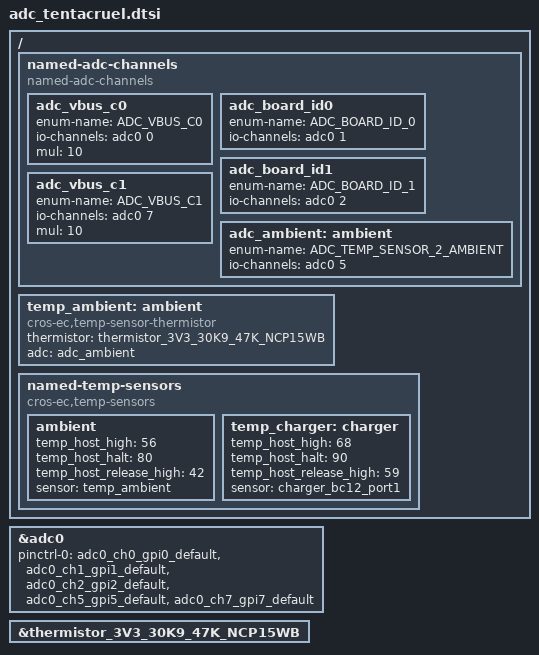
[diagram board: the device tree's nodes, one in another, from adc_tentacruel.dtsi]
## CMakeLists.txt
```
# Copyright 2021 The ChromiumOS Authors
# Use of this source code is governed by a BSD-style license that can be
# found in the LICENSE file.

cmake_minimum_required(VERSION 3.13.1)

find_package(Zephyr REQUIRED HINTS "${ZEPHYR_BASE}")

cros_ec_library_include_directories(include)

# Include selected EC source from the baseboard
zephyr_library_sources(
	"src/board.c"
	"src/hibernate.c"
)

zephyr_library_sources_ifdef(CONFIG_PLATFORM_EC_USBC "src/usbc.c")
zephyr_library_sources_ifdef(CONFIG_PLATFORM_EC_USBC "src/usb_pd_policy.c")
zephyr_library_sources_ifdef(CONFIG_VARIANT_CORSOLA_DB_DETECTION
			     "src/variant_db_detection.c")
zephyr_library_sources_ifndef(CONFIG_CORSOLA_BOARD_CHIPSET_CUSTOM "src/board_chipset.c")

if(DEFINED CONFIG_BOARD_KRABBY)
	project(krabby)
	add_subdirectory(krabby)
elseif(DEFINED CONFIG_BOARD_KINGLER)
	project(kingler)
	add_subdirectory(kingler)
elseif(DEFINED CONFIG_BOARD_KYOGRE)
	project(kyogre)
	add_subdirectory(kyogre)
elseif(DEFINED CONFIG_BOARD_STARMIE)
	project(starmie)
	add_subdirectory(starmie)
elseif(DEFINED CONFIG_BOARD_STEELIX)
	project(steelix)
	add_subdirectory(steelix)
elseif(DEFINED CONFIG_BOARD_TENTACRUEL)
	project(tentacruel)
	add_subdirectory(tentacruel)
elseif(DEFINED CONFIG_BOARD_MAGIKARP)
	project(magikarp)
	add_subdirectory(magikarp)
elseif(DEFINED CONFIG_BOARD_VOLTORB)
	project(voltorb)
	add_subdirectory(voltorb)
elseif(DEFINED CONFIG_BOARD_PONYTA)
	project(ponyta)
	add_subdirectory(ponyta)
elseif(DEFINED CONFIG_BOARD_CHINCHOU)
	project(chinchou)
	add_subdirectory(chinchou)
elseif(DEFINED CONFIG_BOARD_WOOBAT)
	project(woobat)
	add_subdirectory(woobat)
elseif(DEFINED CONFIG_BOARD_WUGTRIO)
	project(wugtrio)
	add_subdirectory(wugtrio)
elseif(DEFINED CONFIG_BOARD_SKITTY)
	project(skitty)
	add_subdirectory(skitty)
elseif(DEFINED CONFIG_BOARD_VELUZA)
	project(veluza)
	add_subdirectory(veluza)
elseif(DEFINED CONFIG_BOARD_SQUIRTLE)
	project(squirtle)
	add_subdirectory(squirtle)
elseif(DEFINED CONFIG_BOARD_WYRDEER)
	project(wyrdeer)
	add_subdirectory(wyrdeer)
endif()
```

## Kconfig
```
# Copyright 2021 The ChromiumOS Authors
# Use of this source code is governed by a BSD-style license that can be
# found in the LICENSE file.

config BOARD_KRABBY
	bool "Google Krabby Board"
	help
	  Build Google Krabby reference board. Krabby has MediaTek MT8186 SoC
	  with ITE it81202-bx EC.

config BOARD_KINGLER
	bool "Google Kingler Board"
	help
	  Build Google Kingler reference board. Krabby has MediaTek MT8186 SoC
	  with NPCX993FA0BX EC.

config BOARD_KYOGRE
	bool "Google Kyogre Board"
	help
	  Build Google Kyogre variant board. Kyogre is a variant of Kingler
	  and has MediaTek MT8186 SoC with NPCX993FA0BX EC.

config BOARD_STARMIE
	bool "Google Starmie Board"
	help
	  Build Google Starmie variant board. Starmie is a variant of Krabby
	  and has MediaTek MT8186 SoC with ITE it81202-bx EC

config BOARD_STEELIX
	bool "Google Steelix Board"
	help
	  Build Google Steelix variant board. Steelix is a variant of Kingler
	  and has MediaTek MT8186 SoC with NPCX993FA0BX EC.

config BOARD_TENTACRUEL
	bool "Google Tentacruel Board"
	help
	  Build Google Tentacruel variant board. Tentacruel is a variant of Krabby
	  and has MediaTek MT8186 SoC with ITE it81202-bx EC.

config BOARD_MAGIKARP
	bool "Google Magikarp Board"
	help
	  Build Google Magikarp variant board. Magikarp is a variant of Krabby
	  and has MediaTek MT8186 SoC with ITE it81202-bx EC.

config BOARD_VOLTORB
	bool "Google Voltorb Board"
	help
	  Build Google Voltorb variant board. Voltorb is a variant of Kingler
	  and has MediaTek MT8186/MT8186T SoC with NPCX993FA0BX EC.

config BOARD_PONYTA
	bool "Google Ponyta Board"
	help
	  Build Google Ponyta variant board. Ponyta is a variant of Kingler
	  and has MediaTek MT8186 SoC with NPCX993FA0BX EC.

config BOARD_CHINCHOU
	bool "Google Chinchou Board"
	help
	  Build Google Chinchou variant board. Chinchou is a variant of Krabby
	  and has MediaTek MT8186 SoC with ITE it81202-bx EC

config BOARD_WOOBAT
	bool "Google Woobat Board"
	help
	  Build Google Woobat variant board. Woobat is a variant of Krabby
	  and has MediaTek MT8186 SoC with ITE it81202-bx EC

config BOARD_WUGTRIO
	bool "Google Wugtrio Board"
	help
	  Build Google Wugtrio variant board. Wugtrio is a variant of Krabby
	  and has MediaTek MT8186 SoC with ITE it81202-bx EC

config BOARD_SKITTY
	bool "Google Skitty Board"
	help
	  Build Google Skitty variant board. Skitty is a variant of Krabby
	  and has MediaTek MT8186 SoC with ITE it81202-bx EC

config BOARD_VELUZA
	bool "Google Veluza Board"
	help
	  Build Google Veluza variant board. Veluza is a variant of Krabby
	  and has MediaTek MT8186 SoC with ITE it81202-bx EC

config BOARD_SQUIRTLE
	bool "Google Squirtle Board"
	help
	  Build Google Squirtle variant board. Squirtle is a variant of Kingler
	  and has MediaTek MT8186/MT8186T SoC with NPCX993FA0BX EC.

config BOARD_WYRDEER
	bool "Google Wyrdeer Board"
	help
	  Build Google Wyrdeer variant board. Wyrdeer is a variant of Krabby
	  and has MediaTek MT8186 SoC with ITE it81202-bx EC

config VARIANT_CORSOLA_DB_DETECTION
	bool "Corsola Platform Runtime Daughter Board Detection"
	depends on PLATFORM_EC_USB_PD_TCPC_RUNTIME_CONFIG
	depends on PLATFORM_EC_USB_MUX_RUNTIME_CONFIG
	help
	  Daughter board detection for Type-C subboard or HDMI subboard. This
          includes pin configuration and driver loading.
	default y

config CORSOLA_HIBERNATE_PRE_OFF_5V
	bool "Corsola Platform Hibernate Power Sequence Selection"
	help
	  Set PP5000_Z2 to deactivate before executing normal corsola hibernate.
	default n

config CORSOLA_BOARD_CHIPSET_CUSTOM
	bool "Corsola Platform Board Chipset Customization"
	help
	  Enable corsola platform customized AP power callbacks.
	default n

source "Kconfig.zephyr"
```

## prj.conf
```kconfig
# Copyright 2021 The ChromiumOS Authors
# Use of this source code is governed by a BSD-style license that can be
# found in the LICENSE file.
#

# http://google3/hardware/standards/usb/
CONFIG_PLATFORM_EC_USB_PID=0x505C

# CROS EC
CONFIG_CROS_EC=y
CONFIG_PLATFORM_EC=y
CONFIG_PLATFORM_EC_SWITCH=y
CONFIG_SHIMMED_TASKS=y

# AP SoC configuration
CONFIG_AP=y
CONFIG_AP_ARM_MTK_MT8186=y

# Variant config
CONFIG_VARIANT_CORSOLA_DB_DETECTION=y

# Shell features
CONFIG_KERNEL_SHELL=y
CONFIG_SHELL_HELP=y
CONFIG_SHELL_HISTORY=y
CONFIG_SHELL_TAB=y
CONFIG_SHELL_TAB_AUTOCOMPLETION=y

# CBI
CONFIG_EEPROM=y
CONFIG_EEPROM_SHELL=n
CONFIG_PLATFORM_EC_BOARD_VERSION_CBI=y

# Keyboard
CONFIG_PLATFORM_EC_KEYBOARD=y
CONFIG_PLATFORM_EC_KEYBOARD_PROTOCOL_MKBP=y
CONFIG_PLATFORM_EC_KEYBOARD_COL2_INVERTED=y

# MKBP
CONFIG_PLATFORM_EC_MKBP_EVENT=y
CONFIG_PLATFORM_EC_MKBP_INPUT_DEVICES=y
CONFIG_PLATFORM_EC_MKBP_USE_GPIO=y

# EFS2
CONFIG_PLATFORM_EC_VBOOT_EFS2=y

# USB
CONFIG_PLATFORM_EC_USB_PD_TBT_COMPAT_MODE=n
CONFIG_PLATFORM_EC_USB_PD_USB32_DRD=n
CONFIG_PLATFORM_EC_USB_PD_USB4=n
CONFIG_PLATFORM_EC_USB_PORT_POWER_DUMB_CUSTOM_HOOK=y

# USB-C
CONFIG_PLATFORM_EC_USBC=y
CONFIG_PLATFORM_EC_USBC_SS_MUX_DFP_ONLY=y
CONFIG_PLATFORM_EC_USB_PD_DPS=y
CONFIG_PLATFORM_EC_USB_PD_DP_HPD_GPIO=y
CONFIG_PLATFORM_EC_USB_PD_DP_HPD_GPIO_CUSTOM=y
CONFIG_PLATFORM_EC_USB_PD_FRS=y
CONFIG_PLATFORM_EC_USB_PD_CLEAR_HARD_RESET_STATUS=y

# Power Seq
CONFIG_PLATFORM_EC_CHIPSET_RESUME_INIT_HOOK=y
CONFIG_PLATFORM_EC_EXTPOWER_GPIO=y
CONFIG_PLATFORM_EC_POWERSEQ=y
CONFIG_PLATFORM_EC_POWERSEQ_HOST_SLEEP=y
CONFIG_PLATFORM_EC_POWERSEQ_PP5000_CONTROL=n
CONFIG_PLATFORM_EC_POWER_SLEEP_FAILURE_DETECTION=y

# Optional features
CONFIG_FLASH_SHELL=n

# EEPROM
CONFIG_PLATFORM_EC_EEPROM_CBI_WP=y

# Host Commands
CONFIG_PLATFORM_EC_HOSTCMD=y

# Battery
CONFIG_PLATFORM_EC_BATTERY_CUT_OFF=y
CONFIG_PLATFORM_EC_BATTERY_FUEL_GAUGE=y
CONFIG_PLATFORM_EC_BATTERY_PRESENT_GPIO=y
CONFIG_PLATFORM_EC_BATTERY_SMART=y
CONFIG_PLATFORM_EC_BATT_FULL_CHIPSET_OFF_INPUT_LIMIT_MV=9000
CONFIG_PLATFORM_EC_I2C_PASSTHRU_RESTRICTED=y
CONFIG_PLATFORM_EC_I2C_VIRTUAL_BATTERY=y

# Charger
CONFIG_PLATFORM_EC_BC12_CLIENT_MODE_ONLY_PI3USB9201=y
CONFIG_PLATFORM_EC_CHARGE_MANAGER=y

# Button
CONFIG_PLATFORM_EC_CMD_BUTTON=y
CONFIG_PLATFORM_EC_POWER_BUTTON=y
CONFIG_PLATFORM_EC_VOLUME_BUTTONS=y
```

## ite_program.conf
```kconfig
# Copyright 2022 The ChromiumOS Authors
# Use of this source code is governed by a BSD-style license that can be
# found in the LICENSE file.

# Bring up options
CONFIG_SHELL_HISTORY_BUFFER=256
CONFIG_PLATFORM_EC_SYSTEM_UNLOCKED=y
CONFIG_PLATFORM_EC_BRINGUP=y

# Power Sequencing
CONFIG_PLATFORM_EC_CHIPSET_RESET_HOOK=y

# Lid Switch
CONFIG_PLATFORM_EC_LID_SWITCH=y

# Charger
CONFIG_PLATFORM_EC_CHARGE_RAMP_HW=y
CONFIG_PLATFORM_EC_CHARGER_DISCHARGE_ON_AC=y
CONFIG_PLATFORM_EC_CHARGER_DISCHARGE_ON_AC_CHARGER=y
CONFIG_PLATFORM_EC_CHARGER_MAINTAIN_VBAT=y
CONFIG_PLATFORM_EC_CHARGER_PSYS=y
CONFIG_PLATFORM_EC_CHARGER_PSYS_READ=y
# BOARD_RS2
CONFIG_PLATFORM_EC_CHARGER_SENSE_RESISTOR=10
# BOARD_RS1
CONFIG_PLATFORM_EC_CHARGER_SENSE_RESISTOR_AC=20
CONFIG_PLATFORM_EC_CONSOLE_CMD_CHARGER_DUMP=y

# Host Commands
CONFIG_PLATFORM_EC_CONSOLE_CMD_ACCELS=y
CONFIG_PLATFORM_EC_CONSOLE_CMD_ACCEL_INFO=y
CONFIG_PLATFORM_EC_CONSOLE_CMD_CHARGER_ADC_AMON_BMON=y
CONFIG_PLATFORM_EC_CONSOLE_CMD_SYSINFO=y
CONFIG_PLATFORM_EC_HOST_COMMAND_STATUS=y

# Sensors
CONFIG_PLATFORM_EC_ACCEL_FIFO=y
CONFIG_PLATFORM_EC_GMR_TABLET_MODE=y
CONFIG_PLATFORM_EC_LID_ANGLE=y
CONFIG_PLATFORM_EC_LID_ANGLE_UPDATE=y
CONFIG_PLATFORM_EC_SENSOR_TIGHT_TIMESTAMPS=y
CONFIG_PLATFORM_EC_TABLET_MODE=y
CONFIG_PLATFORM_EC_TABLET_MODE_SWITCH=y
CONFIG_PLATFORM_EC_MAX_SENSOR_FREQ_MILLIHZ=100000

# Sensor Drivers
CONFIG_PLATFORM_EC_ACCEL_LIS2DW12=y
CONFIG_PLATFORM_EC_ACCELGYRO_ICM42607=y
CONFIG_PLATFORM_EC_ACCELGYRO_ICM_COMM_I2C=y

# Tasks
CONFIG_TASK_CHARGER_STACK_SIZE=1440
CONFIG_TASK_CHIPSET_STACK_SIZE=1440
CONFIG_TASK_MOTIONSENSE_STACK_SIZE=1280
CONFIG_TASK_PD_STACK_SIZE=1280

# USB-C
CONFIG_PLATFORM_EC_USBC_PPC_SYV682C=y
CONFIG_PLATFORM_EC_USB_PD_DISCHARGE_PPC=y
CONFIG_PLATFORM_EC_USB_PD_FRS_PPC=y
CONFIG_PLATFORM_EC_USB_PD_LOGGING=y
CONFIG_PLATFORM_EC_USB_PD_VBUS_DETECT_PPC=y
CONFIG_PLATFORM_EC_USB_PD_VBUS_MEASURE_ADC_EACH_PORT=y
CONFIG_PLATFORM_EC_USB_PD_DUAL_ROLE_AUTO_TOGGLE=n
CONFIG_PLATFORM_EC_USB_PD_3A_PORTS=0
CONFIG_PLATFORM_EC_USB_PD_PULLUP=1

# TODO(b/180980668): bring these features up
CONFIG_PLATFORM_EC_BACKLIGHT_LID=n

# Decrease TX shell backend buffer to save RAM
CONFIG_SHELL_BACKEND_SERIAL_TX_RING_BUFFER_SIZE=128
```

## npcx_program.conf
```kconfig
# Copyright 2022 The ChromiumOS Authors
# Use of this source code is governed by a BSD-style license that can be
# found in the LICENSE file.


# Bring up options
CONFIG_PLATFORM_EC_SYSTEM_UNLOCKED=y

# Debug options and features; can be disabled to save memory or once bringup
# is complete.
CONFIG_SHELL_MINIMAL=n

# Charger
CONFIG_PLATFORM_EC_CHARGER_DISCHARGE_ON_AC=y
CONFIG_PLATFORM_EC_CHARGER_ISL9238C=y
CONFIG_PLATFORM_EC_CHARGER_PSYS=y
CONFIG_PLATFORM_EC_CHARGER_PSYS_READ=y
CONFIG_PLATFORM_EC_CHARGER_SENSE_RESISTOR=10
CONFIG_PLATFORM_EC_CHARGER_SENSE_RESISTOR_AC=20
CONFIG_PLATFORM_EC_CONSOLE_CMD_CHARGER_ADC_AMON_BMON=y

# PWM
CONFIG_PWM=y

# LED
CONFIG_PLATFORM_EC_LED_COMMON=y
CONFIG_PLATFORM_EC_LED_ONOFF_STATES=y

# Math
CONFIG_PLATFORM_EC_MATH_UTIL=y

# Power sequencing
CONFIG_PLATFORM_EC_POWERSEQ_MT8186=y
CONFIG_PLATFORM_EC_POWERSEQ_S4=n

# Button
CONFIG_PLATFORM_EC_BUTTONS_RUNTIME_CONFIG=y

# Sensors
CONFIG_PLATFORM_EC_ACCELGYRO_BMI3XX=y
CONFIG_PLATFORM_EC_ACCELGYRO_BMI_COMM_I2C=y
CONFIG_PLATFORM_EC_ACCEL_FIFO=y
CONFIG_PLATFORM_EC_CONSOLE_CMD_ACCELS=y
CONFIG_PLATFORM_EC_CONSOLE_CMD_ACCEL_INFO=y
CONFIG_PLATFORM_EC_GMR_TABLET_MODE=y
CONFIG_PLATFORM_EC_LID_ANGLE=y
CONFIG_PLATFORM_EC_LID_ANGLE_UPDATE=y
CONFIG_PLATFORM_EC_LID_SWITCH=y
CONFIG_PLATFORM_EC_SENSOR_TIGHT_TIMESTAMPS=y
CONFIG_PLATFORM_EC_TABLET_MODE=y
CONFIG_PLATFORM_EC_TABLET_MODE_SWITCH=y

# USBC
CONFIG_PLATFORM_EC_PD_POWER_SUPPLY_TURN_OFF_DELAY=15000
CONFIG_PLATFORM_EC_PD_POWER_SUPPLY_TURN_ON_DELAY=15000
CONFIG_PLATFORM_EC_USBC_PPC=y
CONFIG_PLATFORM_EC_USBC_PPC_RT1718S=n
CONFIG_PLATFORM_EC_USB_PD_DISCHARGE_PPC=y
CONFIG_PLATFORM_EC_USB_PD_FRS_TCPC=y
CONFIG_PLATFORM_EC_USB_PD_LOGGING=y
CONFIG_PLATFORM_EC_USB_PD_DEBUG_FIXED_LEVEL=y
CONFIG_PLATFORM_EC_USB_PD_DEBUG_LEVEL=2
CONFIG_PLATFORM_EC_USB_PD_TCPM_ANX7447_AUX_PU_PD=y
CONFIG_PLATFORM_EC_USB_PD_TCPM_SBU=y
CONFIG_PLATFORM_EC_USB_PD_VBUS_DETECT_TCPC=y
CONFIG_PLATFORM_EC_USB_PD_VBUS_MEASURE_BY_BOARD=y

# External power
CONFIG_PLATFORM_EC_BACKLIGHT_LID=n

# Keyboard
CONFIG_CROS_KB_RAW_NPCX_KSO_HIGH_DRIVE=y

CONFIG_SYSCON=y

CONFIG_PLATFORM_EC_BOARD_VERSION_GPIO=n
```

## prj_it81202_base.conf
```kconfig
# Copyright 2022 The ChromiumOS Authors
# Use of this source code is governed by a BSD-style license that can be
# found in the LICENSE file.

# Bring up options
CONFIG_SHELL_HISTORY_BUFFER=256
CONFIG_PLATFORM_EC_SYSTEM_UNLOCKED=y
CONFIG_PLATFORM_EC_BRINGUP=y

# Power Sequencing
CONFIG_PLATFORM_EC_CHIPSET_RESET_HOOK=y

# Lid Switch
CONFIG_PLATFORM_EC_LID_SWITCH=y

# Charger
CONFIG_PLATFORM_EC_CHARGE_RAMP_HW=y
CONFIG_PLATFORM_EC_CHARGER_DISCHARGE_ON_AC=y
CONFIG_PLATFORM_EC_CHARGER_DISCHARGE_ON_AC_CHARGER=y
CONFIG_PLATFORM_EC_CHARGER_MAINTAIN_VBAT=y
CONFIG_PLATFORM_EC_CHARGER_PSYS=y
CONFIG_PLATFORM_EC_CHARGER_PSYS_READ=y
# BOARD_RS2
CONFIG_PLATFORM_EC_CHARGER_SENSE_RESISTOR=10
# BOARD_RS1
CONFIG_PLATFORM_EC_CHARGER_SENSE_RESISTOR_AC=20
CONFIG_PLATFORM_EC_CONSOLE_CMD_CHARGER_DUMP=y

# Host Commands
CONFIG_PLATFORM_EC_CONSOLE_CMD_ACCELS=y
CONFIG_PLATFORM_EC_CONSOLE_CMD_ACCEL_INFO=y
CONFIG_PLATFORM_EC_CONSOLE_CMD_CHARGER_ADC_AMON_BMON=y
CONFIG_PLATFORM_EC_CONSOLE_CMD_SYSINFO=y
CONFIG_PLATFORM_EC_HOST_COMMAND_STATUS=y

# LED
CONFIG_PLATFORM_EC_LED_DT=y

# PWM
CONFIG_PWM=y
CONFIG_PWM_SHELL=n

# Sensors
CONFIG_PLATFORM_EC_MOTIONSENSE=y
CONFIG_PLATFORM_EC_ACCEL_FIFO=y
CONFIG_PLATFORM_EC_GMR_TABLET_MODE=y
CONFIG_PLATFORM_EC_LID_ANGLE=y
CONFIG_PLATFORM_EC_LID_ANGLE_UPDATE=y
CONFIG_PLATFORM_EC_SENSOR_TIGHT_TIMESTAMPS=y
CONFIG_PLATFORM_EC_TABLET_MODE=y
CONFIG_PLATFORM_EC_TABLET_MODE_SWITCH=y
CONFIG_PLATFORM_EC_MAX_SENSOR_FREQ_MILLIHZ=100000

# Sensor Drivers
CONFIG_PLATFORM_EC_ACCEL_LIS2DW12=y
CONFIG_PLATFORM_EC_ACCELGYRO_ICM42607=y
CONFIG_PLATFORM_EC_ACCELGYRO_ICM_COMM_I2C=y

# Tasks
CONFIG_TASK_CHARGER_STACK_SIZE=1024
CONFIG_TASK_CHIPSET_STACK_SIZE=1440
CONFIG_TASK_MOTIONSENSE_STACK_SIZE=1024
CONFIG_TASK_PD_STACK_SIZE=1280

# USB-A
CONFIG_PLATFORM_EC_USBA=y

# USB-C
CONFIG_PLATFORM_EC_BC12_SINGLE_DRIVER=n
CONFIG_PLATFORM_EC_USBC_PPC_RT1739=y
CONFIG_PLATFORM_EC_USBC_PPC_SYV682C=y
CONFIG_PLATFORM_EC_USBC_PPC_SYV682X=y
CONFIG_PLATFORM_EC_USB_MUX_IT5205=y
CONFIG_PLATFORM_EC_USB_MUX_TUSB546=y
CONFIG_PLATFORM_EC_USB_MUX_VIRTUAL=y
CONFIG_PLATFORM_EC_USB_PD_DISCHARGE_PPC=y
CONFIG_PLATFORM_EC_USB_PD_FRS_PPC=y
CONFIG_PLATFORM_EC_USB_PD_LOGGING=y
CONFIG_PLATFORM_EC_USB_PD_TCPM_DRIVER_IT8XXX2=y
CONFIG_PLATFORM_EC_USB_PD_TCPM_ITE_ON_CHIP=y
CONFIG_PLATFORM_EC_USB_PD_TCPM_TCPCI=y
CONFIG_PLATFORM_EC_USB_PD_VBUS_DETECT_PPC=y
CONFIG_PLATFORM_EC_USB_PD_VBUS_MEASURE_ADC_EACH_PORT=y
CONFIG_PLATFORM_EC_USB_PD_DUAL_ROLE_AUTO_TOGGLE=n
CONFIG_PLATFORM_EC_CONFIG_USB_PD_3A_PORTS=0
CONFIG_PLATFORM_EC_USB_PD_PULLUP=1

CONFIG_PLATFORM_EC_SHA256_UNROLLED=y

# TODO(b/180980668): bring these features up
CONFIG_LTO=n
CONFIG_PLATFORM_EC_BACKLIGHT_LID=n
```

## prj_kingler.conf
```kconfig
# Copyright 2021 The ChromiumOS Authors
# Use of this source code is governed by a BSD-style license that can be
# found in the LICENSE file.

# Variant config
CONFIG_BOARD_KINGLER=y

# LED
CONFIG_PLATFORM_EC_LED_PWM=y

# Keyboard
CONFIG_PLATFORM_EC_KEYBOARD_PWRBTN_ASSERTS_KSI2=y
```

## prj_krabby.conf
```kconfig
# Copyright 2021 The ChromiumOS Authors
# Use of this source code is governed by a BSD-style license that can be
# found in the LICENSE file.

# Variant config
CONFIG_BOARD_KRABBY=y

# Keyboard
CONFIG_PLATFORM_EC_KEYBOARD_PWRBTN_ASSERTS_KSI2=y
```

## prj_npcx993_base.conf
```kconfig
# Copyright 2022 The ChromiumOS Authors
# Use of this source code is governed by a BSD-style license that can be
# found in the LICENSE file.


# Bring up options
CONFIG_PLATFORM_EC_SYSTEM_UNLOCKED=y

# Debug options and features; can be disabled to save memory or once bringup
# is complete.
CONFIG_SHELL_MINIMAL=n
CONFIG_LOG=y
CONFIG_LOG_MODE_MINIMAL=y

# Charger
CONFIG_PLATFORM_EC_CHARGER_DISCHARGE_ON_AC=y
CONFIG_PLATFORM_EC_CHARGER_ISL9238C=y
CONFIG_PLATFORM_EC_CHARGER_PSYS=y
CONFIG_PLATFORM_EC_CHARGER_PSYS_READ=y
CONFIG_PLATFORM_EC_CHARGER_SENSE_RESISTOR=10
CONFIG_PLATFORM_EC_CHARGER_SENSE_RESISTOR_AC=20
CONFIG_PLATFORM_EC_CONSOLE_CMD_CHARGER_ADC_AMON_BMON=y

# PWM
CONFIG_PWM=y
CONFIG_PWM_SHELL=n

# LED
CONFIG_PLATFORM_EC_LED_COMMON=y
CONFIG_PLATFORM_EC_LED_ONOFF_STATES=y

# Math
CONFIG_PLATFORM_EC_MATH_UTIL=y

# Power sequencing
CONFIG_PLATFORM_EC_POWERSEQ_MT8186=y
CONFIG_PLATFORM_EC_POWERSEQ_S4=n

# Button
CONFIG_PLATFORM_EC_BUTTONS_RUNTIME_CONFIG=y

# Sensors
CONFIG_PLATFORM_EC_ACCELGYRO_BMI3XX=y
CONFIG_PLATFORM_EC_ACCELGYRO_BMI_COMM_I2C=y
CONFIG_PLATFORM_EC_ACCEL_BMA4XX=y
CONFIG_PLATFORM_EC_ACCEL_FIFO=y
CONFIG_PLATFORM_EC_CONSOLE_CMD_ACCELS=y
CONFIG_PLATFORM_EC_CONSOLE_CMD_ACCEL_INFO=y
CONFIG_PLATFORM_EC_GMR_TABLET_MODE=y
CONFIG_PLATFORM_EC_LID_ANGLE=y
CONFIG_PLATFORM_EC_LID_ANGLE_UPDATE=y
CONFIG_PLATFORM_EC_LID_SWITCH=y
CONFIG_PLATFORM_EC_MOTIONSENSE=y
CONFIG_PLATFORM_EC_SENSOR_TIGHT_TIMESTAMPS=y
CONFIG_PLATFORM_EC_TABLET_MODE=y
CONFIG_PLATFORM_EC_TABLET_MODE_SWITCH=y

# USBC
CONFIG_PLATFORM_EC_BC12_DETECT_PI3USB9201=y
CONFIG_PLATFORM_EC_BC12_SINGLE_DRIVER=n
CONFIG_PLATFORM_EC_PD_POWER_SUPPLY_TURN_OFF_DELAY=15000
CONFIG_PLATFORM_EC_PD_POWER_SUPPLY_TURN_ON_DELAY=15000
CONFIG_PLATFORM_EC_USBC_PPC=y
CONFIG_PLATFORM_EC_USBC_PPC_NX20P3483=y
CONFIG_PLATFORM_EC_USBC_PPC_RT1718S=y
CONFIG_PLATFORM_EC_USB_MUX_PS8743=y
CONFIG_PLATFORM_EC_USB_MUX_VIRTUAL=y
CONFIG_PLATFORM_EC_USB_PD_DISCHARGE_PPC=y
CONFIG_PLATFORM_EC_USB_PD_FRS_TCPC=y
CONFIG_PLATFORM_EC_USB_PD_LOGGING=y
CONFIG_PLATFORM_EC_USB_PD_DEBUG_FIXED_LEVEL=y
CONFIG_PLATFORM_EC_USB_PD_DEBUG_LEVEL=2
CONFIG_PLATFORM_EC_USB_PD_TCPM_ANX7447=y
CONFIG_PLATFORM_EC_USB_PD_TCPM_ANX7447_AUX_PU_PD=y
CONFIG_PLATFORM_EC_USB_PD_TCPM_RT1718S=y
CONFIG_PLATFORM_EC_USB_PD_TCPM_SBU=y
CONFIG_PLATFORM_EC_USB_PD_VBUS_DETECT_TCPC=y
CONFIG_PLATFORM_EC_USB_PD_VBUS_MEASURE_BY_BOARD=y

# External power
CONFIG_PLATFORM_EC_BACKLIGHT_LID=n

# Keyboard
CONFIG_CROS_KB_RAW_NPCX_KSO_HIGH_DRIVE=y

CONFIG_SYSCON=y

CONFIG_PLATFORM_EC_BOARD_VERSION_GPIO=n
```

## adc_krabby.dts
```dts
/* Copyright 2021 The ChromiumOS Authors
 * Use of this source code is governed by a BSD-style license that can be
 * found in the LICENSE file.
 */

/ {
	named-adc-channels {
		compatible = "named-adc-channels";

		adc_vbus_c0 {
			enum-name = "ADC_VBUS_C0";
			io-channels = <&adc0 0>;
			mul = <10>;
		};
		adc_board_id0 {
			enum-name = "ADC_BOARD_ID_0";
			io-channels = <&adc0 1>;
		};
		adc_board_id1 {
			enum-name = "ADC_BOARD_ID_1";
			io-channels = <&adc0 2>;
		};
		adc_vbus_c1 {
			enum-name = "ADC_VBUS_C1";
			io-channels = <&adc0 7>;
			mul = <10>;
		};
	};
};

&adc0 {
	status = "okay";
	pinctrl-0 = <&adc0_ch0_gpi0_default
		     &adc0_ch1_gpi1_default
		     &adc0_ch2_gpi2_default
		     &adc0_ch7_gpi7_default>;
	pinctrl-names = "default";
};
```

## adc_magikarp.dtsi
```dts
/* Copyright 2022 The ChromiumOS Authors
 * Use of this source code is governed by a BSD-style license that can be
 * found in the LICENSE file.
 */

#include <cros/thermistor/thermistor.dtsi>

/ {
	named-adc-channels {
		compatible = "named-adc-channels";
		adc_vbus_c0 {
			enum-name = "ADC_VBUS_C0";
			io-channels = <&adc0 0>;
			mul = <10>;
		};
		adc_board_id0 {
			enum-name = "ADC_BOARD_ID_0";
			io-channels = <&adc0 1>;
		};
		adc_board_id1 {
			enum-name = "ADC_BOARD_ID_1";
			io-channels = <&adc0 2>;
		};
		adc_vbus_c1 {
			enum-name = "ADC_VBUS_C1";
			io-channels = <&adc0 7>;
			mul = <10>;
		};
		adc_ambient: ambient {
			enum-name = "ADC_TEMP_SENSOR_2_AMBIENT";
			io-channels = <&adc0 5>;
		};
	};
};

&adc0 {
	status = "okay";
	pinctrl-0 = <&adc0_ch0_gpi0_default
		     &adc0_ch1_gpi1_default
		     &adc0_ch2_gpi2_default
		     &adc0_ch5_gpi5_default
		     &adc0_ch7_gpi7_default>;
	pinctrl-names = "default";
};

/ {
	temp_ambient: ambient {
		compatible = "cros-ec,temp-sensor-thermistor";
		thermistor = <&thermistor_3V3_30K9_47K_NCP15WB>;
		adc = <&adc_ambient>;
	};

	named-temp-sensors {
		compatible = "cros-ec,temp-sensors";
		ambient {
			sensor = <&temp_ambient>;
		};
	};
};

&thermistor_3V3_30K9_47K_NCP15WB {
	status = "okay";
};
```

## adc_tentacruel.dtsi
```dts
/* Copyright 2022 The ChromiumOS Authors
 * Use of this source code is governed by a BSD-style license that can be
 * found in the LICENSE file.
 */

#include <cros/thermistor/thermistor.dtsi>

/ {
	named-adc-channels {
		compatible = "named-adc-channels";
		adc_vbus_c0 {
			enum-name = "ADC_VBUS_C0";
			io-channels = <&adc0 0>;
			mul = <10>;
		};
		adc_board_id0 {
			enum-name = "ADC_BOARD_ID_0";
			io-channels = <&adc0 1>;
		};
		adc_board_id1 {
			enum-name = "ADC_BOARD_ID_1";
			io-channels = <&adc0 2>;
		};
		adc_vbus_c1 {
			enum-name = "ADC_VBUS_C1";
			io-channels = <&adc0 7>;
			mul = <10>;
		};
		adc_ambient: ambient {
			enum-name = "ADC_TEMP_SENSOR_2_AMBIENT";
			io-channels = <&adc0 5>;
		};
	};
};

&adc0 {
	status = "okay";
	pinctrl-0 = <&adc0_ch0_gpi0_default
		     &adc0_ch1_gpi1_default
		     &adc0_ch2_gpi2_default
		     &adc0_ch5_gpi5_default
		     &adc0_ch7_gpi7_default>;
	pinctrl-names = "default";
};

/ {
	temp_ambient: ambient {
		compatible = "cros-ec,temp-sensor-thermistor";
		thermistor = <&thermistor_3V3_30K9_47K_NCP15WB>;
		adc = <&adc_ambient>;
	};

	named-temp-sensors {
		compatible = "cros-ec,temp-sensors";
		ambient {
			temp_host_high = <56>;
			temp_host_halt = <80>;
			temp_host_release_high = <42>;
			sensor = <&temp_ambient>;
		};
		temp_charger: charger {
			temp_host_high = <68>;
			temp_host_halt = <90>;
			temp_host_release_high = <59>;
			sensor = <&charger_bc12_port1>;
		};
	};
};

&thermistor_3V3_30K9_47K_NCP15WB {
	status = "okay";
};
```

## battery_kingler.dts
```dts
/* Copyright 2021 The ChromiumOS Authors
 * Use of this source code is governed by a BSD-style license that can be
 * found in the LICENSE file.
 */

/ {
	batteries {
		default_battery: smp_l20m3pg2 {
			compatible = "smp,l20m3pg2", "battery-smart";
		};
		lgc_l20l3pg2 {
			compatible = "lgc,l20l3pg2", "battery-smart";
		};
	};
};
```

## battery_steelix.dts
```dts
/* Copyright 2021 The ChromiumOS Authors
 * Use of this source code is governed by a BSD-style license that can be
 * found in the LICENSE file.
 */

/ {
	batteries {
		default_battery: byd_l22b3pg0 {
			compatible = "byd,l22b3pg0", "battery-smart";
		};
		celxpert_l22c3pg0 {
			compatible = "celxpert,l22c3pg0", "battery-smart";
		};
		cosmx_l22x3pg0 {
			compatible = "cosmx,l22x3pg0", "battery-smart";
		};
		smp_l22m3pg0 {
			compatible = "smp,l22m3pg0", "battery-smart";
		};
		sunwoda_l22d3pg0 {
			compatible = "sunwoda,l22d3pg0", "battery-smart";
		};
	};
};
```

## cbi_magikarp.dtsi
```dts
/* Copyright 2022 The ChromiumOS Authors
 * Use of this source code is governed by a BSD-style license that can be
 * found in the LICENSE file.
 */

/ {
	/* magikarp-specific fw_config fields. */
	magikarp-fw-config {
		compatible = "cros-ec,cbi-fw-config";
		/*
		 * FW_CONFIG field to describe mainboard orientation in chassis.
		 */
		base-gyro {
			enum-name = "FW_BASE_GYRO";
			start = <0>;
			size = <2>;

			None {
				compatible = "cros-ec,cbi-fw-config-value";
				enum-name = "FW_BASE_NONE";
				value = <0>;
			};
			icm42607 {
				compatible = "cros-ec,cbi-fw-config-value";
				enum-name = "FW_BASE_ICM42607";
				value = <1>;
				default;
			};
			bmi323 {
				compatible = "cros-ec,cbi-fw-config-value";
				enum-name = "FW_BASE_BMI323";
				value = <2>;
			};
		};
	};
};
```

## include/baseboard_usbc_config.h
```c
/* Copyright 2021 The ChromiumOS Authors
 * Use of this source code is governed by a BSD-style license that can be
 * found in the LICENSE file.
 */

/* Corsola daughter board detection */

#ifndef __CROS_EC_BASEBOARD_USBC_CONFIG_H
#define __CROS_EC_BASEBOARD_USBC_CONFIG_H

#include "gpio.h"

#include <zephyr/sys/util_macro.h>

#ifdef CONFIG_PLATFORM_EC_USB_PD_TCPM_RT1718S
#define GPIO_EN_USB_C1_SINK RT1718S_GPIO1
#define GPIO_EN_USB_C1_SOURCE RT1718S_GPIO2
#define GPIO_EN_USB_C1_FRS RT1718S_GPIO3
#endif

void ppc_interrupt(enum gpio_signal signal);
void ccd_interrupt(enum gpio_signal signal);
void hdmi_hpd_interrupt(enum gpio_signal signal);
void ps185_hdmi_hpd_mux_set(void);
int corsola_is_dp_muxable(int port);
int ps8743_eq_c1_setting(void);

/* USB-A ports */
enum usba_port { USBA_PORT_A0 = 0, USBA_PORT_COUNT };

/* USB-C ports */
#define USBC_PORT_N(i, _) USBC_PORT_C##i = i
enum usbc_port {
	LISTIFY(CONFIG_USB_PD_PORT_MAX_COUNT, USBC_PORT_N, (, )),
	USBC_PORT_COUNT
};

/**
 * Is the port fine to be muxed its DisplayPort lines?
 *
 * Only one port can be muxed to DisplayPort at a time.
 *
 * @param port	Port number of TCPC.
 * @return	1 is fine; 0 is bad as other port is already muxed;
 */
int corsola_is_dp_muxable(int port);

#endif /* __CROS_EC_BASEBOARD_USBC_CONFIG_H */
```

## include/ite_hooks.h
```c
/* Copyright 2025 The ChromiumOS Authors
 * Use of this source code is governed by a BSD-style license that can be
 * found in the LICENSE file.
 */

/* Corsola Hook function  */

#ifndef __CROS_EC_ITE_HOOKS_H
#define __CROS_EC_ITE_HOOKS_H

#include "common.h"

__override_proto void board_rt9490_adc_control(void);

#endif /* __CROS_EC_ITE_HOOKS_H */
```

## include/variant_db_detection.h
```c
/* Copyright 2021 The ChromiumOS Authors
 * Use of this source code is governed by a BSD-style license that can be
 * found in the LICENSE file.
 */

/* Corsola daughter board detection */

#ifndef __CROS_EC_CORSOLA_DB_DETECTION_H
#define __CROS_EC_CORSOLA_DB_DETECTION_H

#include <stdint.h>

enum corsola_db_type {
	CORSOLA_DB_UNINIT = -1,
	/* CORSOLA_DB_NO_DETECTION means there is no detection involved in. */
	CORSOLA_DB_NO_DETECTION,
	/* CORSOLA_DB_NONE means there is no DB in the design. */
	CORSOLA_DB_NONE,
	CORSOLA_DB_TYPEC,
	CORSOLA_DB_HDMI,
	CORSOLA_DB_COUNT,
};

/*
 * Get the connected daughterboard type.
 *
 * @return		The daughterboard type.
 */
#if defined(CONFIG_VARIANT_CORSOLA_DB_DETECTION) || defined(CONFIG_TEST)
enum corsola_db_type corsola_get_db_type(void);
#else
inline enum corsola_db_type corsola_get_db_type(void)
{
	return CORSOLA_DB_NO_DETECTION;
}
#endif

/* return the adjusted port count for board overridden usbc/charger functions.
 */
test_mockable uint8_t board_get_adjusted_usb_pd_port_count(void);

#endif /* __CROS_EC_CORSOLA_DB_DETECTION_H */
```

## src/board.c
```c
/* Copyright 2022 The ChromiumOS Authors
 * Use of this source code is governed by a BSD-style license that can be
 * found in the LICENSE file.
 */

#include "baseboard_usbc_config.h"
#include "console.h"
#include "hooks.h"
#include "typec_control.h"

#define CPRINTS(format, args...) cprints(CC_USB, format, ##args)

static void ccd_interrupt_deferred(void)
{
	/*
	 * If CCD_MODE_ODL asserts, it means there's a debug accessory connected
	 * and we should enable the SBU FETs.
	 */
	typec_set_sbu(CONFIG_CCD_USBC_PORT_NUMBER, 1);

	/* Mux DP AUX away when CCD enabled to prevent the AUX channel
	 * interferes the SBU pins.
	 */
	CPRINTS("CCD Enabled, mux DP_AUX_PATH_SEL to 1");
	gpio_pin_set_dt(GPIO_DT_FROM_NODELABEL(dp_aux_path_sel), 1);
}
DECLARE_DEFERRED(ccd_interrupt_deferred);

void ccd_interrupt(enum gpio_signal signal)
{
	hook_call_deferred(&ccd_interrupt_deferred_data, 0);
}
```

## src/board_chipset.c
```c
/* Copyright 2021 The ChromiumOS Authors
 * Use of this source code is governed by a BSD-style license that can be
 * found in the LICENSE file.
 */

/* Corsola baseboard-chipset specific configuration */

#include "gpio_signal.h"

#include <zephyr/drivers/gpio.h>
#include <zephyr/init.h>

#include <ap_power/ap_power.h>

static void board_backlight_handler(struct ap_power_ev_callback *cb,
				    struct ap_power_ev_data data)
{
	int value;

	switch (data.event) {
	default:
		return;

	case AP_POWER_RESUME:
		/* Called on AP S3 -> S0 transition */
		value = 1;
		break;

	case AP_POWER_SUSPEND:
		/* Called on AP S0 -> S3 transition */
		value = 0;
		break;
	}
	gpio_pin_set_dt(GPIO_DT_FROM_NODELABEL(gpio_ec_bl_en_od), value);
}

static int install_backlight_handler(void)
{
	static struct ap_power_ev_callback cb;

	/*
	 * Add a callback for suspend/resume to
	 * control the keyboard backlight.
	 */
	ap_power_ev_init_callback(&cb, board_backlight_handler,
				  AP_POWER_RESUME | AP_POWER_SUSPEND);
	ap_power_ev_add_callback(&cb);
	return 0;
}

SYS_INIT(install_backlight_handler, APPLICATION, 1);
```

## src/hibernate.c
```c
/* Copyright 2021 The ChromiumOS Authors
 * Use of this source code is governed by a BSD-style license that can be
 * found in the LICENSE file.
 */
#include "charger.h"
#include "driver/charger/isl923x_public.h"
#include "system.h"

#include <zephyr/drivers/gpio.h>

/* Corsola board specific hibernate implementation */
__override void board_hibernate(void)
{
#ifdef CONFIG_CHARGER_ISL9238C
	isl9238c_hibernate(CHARGER_SOLO);
#endif
}

__override void board_hibernate_late(void)
{
#ifdef CONFIG_CORSOLA_HIBERNATE_PRE_OFF_5V
	/* b/283037861: Pre-off the 5V power line for hibernate. */
	gpio_pin_set_dt(GPIO_DT_FROM_NODELABEL(en_pp5000_z2), 1);
	/* It takes around 30ms to release the PP5000 capacitance. */
	k_busy_wait(30 * USEC_PER_MSEC);
#endif
	gpio_pin_set_dt(GPIO_DT_FROM_NODELABEL(gpio_en_ulp), 1);
}
```

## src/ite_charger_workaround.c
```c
/* Copyright 2022 The ChromiumOS Authors
 * Use of this source code is governed by a BSD-style license that can be
 * found in the LICENSE file.
 */

#include "charger.h"
#include "driver/charger/rt9490.h"
#include "hooks.h"
#include "i2c.h"
#include "system.h"

#include <zephyr/sys/util.h>

/*
 * This workaround and the board id checks only apply to krabby and early
 * tentacruel devices.
 * Newer project should have all of these fixed.
 */
BUILD_ASSERT(IS_ENABLED(CONFIG_BOARD_KRABBY) ||
	     IS_ENABLED(CONFIG_BOARD_TENTACRUEL) || IS_ENABLED(CONFIG_TEST));

/* b/194967754#comment5: work around for IBUS ADC unstable issue */
static void ibus_adc_workaround(void)
{
	if (system_get_board_version() != 0) {
		return;
	}

	i2c_update8(chg_chips[CHARGER_SOLO].i2c_port,
		    chg_chips[CHARGER_SOLO].i2c_addr_flags,
		    RT9490_REG_ADC_CHANNEL0, RT9490_VSYS_ADC_DIS, MASK_SET);

	rt9490_enable_hidden_mode(CHARGER_SOLO, true);
	/* undocumented registers... */
	i2c_write8(chg_chips[CHARGER_SOLO].i2c_port,
		   chg_chips[CHARGER_SOLO].i2c_addr_flags, 0x52, 0xC4);

	i2c_update8(chg_chips[CHARGER_SOLO].i2c_port,
		    chg_chips[CHARGER_SOLO].i2c_addr_flags,
		    RT9490_REG_ADC_CHANNEL0, RT9490_VSYS_ADC_DIS, MASK_CLR);
	rt9490_enable_hidden_mode(CHARGER_SOLO, false);
}

/* b/214880220#comment44: lock i2c at 400khz */
static void i2c_speed_workaround(void)
{
	if (system_get_board_version() >= 3) {
		return;
	}

	rt9490_enable_hidden_mode(CHARGER_SOLO, true);
	/* Set to Auto mode, default run at 400kHz */
	i2c_write8(chg_chips[CHARGER_SOLO].i2c_port,
		   chg_chips[CHARGER_SOLO].i2c_addr_flags, 0x71, 0x22);
	/* Manually select for 400kHz, valid only when 0x71[7] == 1 */
	i2c_write8(chg_chips[CHARGER_SOLO].i2c_port,
		   chg_chips[CHARGER_SOLO].i2c_addr_flags, 0xF7, 0x14);
	rt9490_enable_hidden_mode(CHARGER_SOLO, false);
}

static void eoc_deglitch_workaround(void)
{
	if (system_get_board_version() != 1) {
		return;
	}

	/* set end-of-charge deglitch time to 2ms */
	i2c_update8(chg_chips[CHARGER_SOLO].i2c_port,
		    chg_chips[CHARGER_SOLO].i2c_addr_flags,
		    RT9490_REG_ADD_CTRL0, RT9490_TD_EOC, MASK_CLR);
}

static void disable_safety_timer(void)
{
	if (system_get_board_version() >= 2) {
		return;
	}
	/* Disable charge timer */
	i2c_write8(chg_chips[CHARGER_SOLO].i2c_port,
		   chg_chips[CHARGER_SOLO].i2c_addr_flags,
		   RT9490_REG_SAFETY_TMR_CTRL,
		   RT9490_EN_TRICHG_TMR | RT9490_EN_PRECHG_TMR |
			   RT9490_EN_FASTCHG_TMR);
}

static void board_rt9490_workaround(void)
{
	ibus_adc_workaround();
	i2c_speed_workaround();
	eoc_deglitch_workaround();
	disable_safety_timer();
}
DECLARE_HOOK(HOOK_INIT, board_rt9490_workaround, HOOK_PRIO_DEFAULT);
```

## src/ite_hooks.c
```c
/* Copyright 2021 The ChromiumOS Authors
 * Use of this source code is governed by a BSD-style license that can be
 * found in the LICENSE file.
 */

#include "charger.h"
#include "driver/charger/rt9490.h"
#include "extpower.h"
#include "hooks.h"
#include "ite_hooks.h"

#include <zephyr/drivers/gpio.h>
#include <zephyr/drivers/pinctrl.h>
#include <zephyr/init.h>

#include <ap_power/ap_power.h>

#define I2C3_NODE DT_NODELABEL(i2c3)
PINCTRL_DT_DEFINE(I2C3_NODE);

static void board_i2c3_ctrl(bool enable)
{
	if (DEVICE_DT_GET(
		    DT_GPIO_CTLR_BY_IDX(DT_NODELABEL(i2c3), scl_gpios, 0)) ==
	    DEVICE_DT_GET(DT_NODELABEL(gpiof))) {
		const struct pinctrl_dev_config *pcfg =
			PINCTRL_DT_DEV_CONFIG_GET(I2C3_NODE);

		if (enable) {
			pinctrl_apply_state(pcfg, PINCTRL_STATE_DEFAULT);
		} else {
			pinctrl_apply_state(pcfg, PINCTRL_STATE_SLEEP);
		}
	}
}

static void board_enable_i2c3(void)
{
	board_i2c3_ctrl(1);
}
DECLARE_HOOK(HOOK_CHIPSET_PRE_INIT, board_enable_i2c3, HOOK_PRIO_FIRST);

static void board_disable_i2c3(void)
{
	board_i2c3_ctrl(0);
}
DECLARE_HOOK(HOOK_CHIPSET_HARD_OFF, board_disable_i2c3, HOOK_PRIO_LAST);

static void board_suspend_handler(struct ap_power_ev_callback *cb,
				  struct ap_power_ev_data data)
{
	int value;

	switch (data.event) {
	default:
		return;

	case AP_POWER_RESUME:
		value = 1;
		break;

	case AP_POWER_SUSPEND:
		value = 0;
		break;
	}
	gpio_pin_set_dt(GPIO_DT_FROM_NODELABEL(gpio_en_5v_usm), value);
}

static int install_suspend_handler(void)
{
	static struct ap_power_ev_callback cb;

	/*
	 * Add a callback for suspend/resume.
	 */
	ap_power_ev_init_callback(&cb, board_suspend_handler,
				  AP_POWER_RESUME | AP_POWER_SUSPEND);
	ap_power_ev_add_callback(&cb);
	return 0;
}

SYS_INIT(install_suspend_handler, APPLICATION, 1);

__overridable void board_rt9490_adc_control(void)
{
	if (system_get_board_version() >= 1) {
		rt9490_enable_adc(CHARGER_SOLO, extpower_is_present());
	}
}

static void board_hook_ac_change(void)
{
	board_rt9490_adc_control();
}
DECLARE_HOOK(HOOK_AC_CHANGE, board_hook_ac_change, HOOK_PRIO_DEFAULT);
DECLARE_HOOK(HOOK_INIT, board_hook_ac_change, HOOK_PRIO_LAST);
```

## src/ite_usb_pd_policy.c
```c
/* Copyright 2021 The ChromiumOS Authors
 * Use of this source code is governed by a BSD-style license that can be
 * found in the LICENSE file.
 */

#include "adc.h"
#include "charge_manager.h"
#include "usb_charge.h"
#include "usb_pd.h"
#include "usbc_ppc.h"

int pd_snk_is_vbus_provided(int port)
{
#ifdef CONFIG_PLATFORM_EC_USB_CHARGER
	static atomic_t vbus_prev[CONFIG_USB_PD_PORT_MAX_COUNT];
#endif
	int vbus;

	/*
	 * (b:181203590#comment20) TODO(yllin): use
	 *  PD_VSINK_DISCONNECT_PD for non-5V case.
	 */
	vbus = adc_read_channel(board_get_vbus_adc(port)) >=
	       PD_V_SINK_DISCONNECT_MAX;

#ifdef CONFIG_PLATFORM_EC_USB_CHARGER
	/*
	 * There's no PPC to inform VBUS change for usb_charger, so inform
	 * the usb_charger now.
	 */
	if (!!(vbus_prev[port] != vbus)) {
		usb_charger_vbus_change(port, vbus);
	}

	if (vbus) {
		atomic_or(&vbus_prev[port], 1);
	} else {
		atomic_clear(&vbus_prev[port]);
	}
#endif
	return vbus;
}

int board_vbus_source_enabled(int port)
{
	return ppc_is_sourcing_vbus(port);
}
```

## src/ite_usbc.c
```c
/* Copyright 2021 The ChromiumOS Authors
 * Use of this source code is governed by a BSD-style license that can be
 * found in the LICENSE file.
 */

/* Krabby board-specific USB-C configuration */

#include "charge_manager.h"
#include "console.h"
#include "driver/tcpm/it83xx_pd.h"
#include "driver/usb_mux/tusb1064.h"
#include "i2c.h"
#include "usb_pd.h"
#include "usbc_ppc.h"
#include "variant_db_detection.h"
#include "zephyr_adc.h"

#include <zephyr/sys/util_macro.h>

#define CPRINTSUSB(format, args...) cprints(CC_USBCHARGE, format, ##args)
#define CPRINTS(format, args...) cprints(CC_SYSTEM, format, ##args)
#define CPRINTF(format, args...) cprintf(CC_SYSTEM, format, ##args)

#define ITE_CC_PARAMETER(i, _)                              \
	{ .rc_filter = IT83XX_TX_RC_FILTER_TRIM,            \
	  .rising_time = IT83XX_TX_PRE_DRIVING_TIME_1_UNIT, \
	  .falling_time = IT83XX_TX_PRE_DRIVING_TIME_2_UNIT }

int tusb1064_mux_1_board_init(const struct usb_mux *me)
{
	int rv;

	rv = i2c_write8(me->i2c_port, me->i2c_addr_flags,
			TUSB1064_REG_DP1DP3EQ_SEL,
			TUSB1064_DP1EQ(TUSB1064_DP_EQ_RX_8_9_DB) |
				TUSB1064_DP3EQ(TUSB1064_DP_EQ_RX_5_4_DB));
	if (rv)
		return rv;

	/* Enable EQ_OVERRIDE so the gain registers are used */
	return i2c_update8(me->i2c_port, me->i2c_addr_flags,
			   TUSB1064_REG_GENERAL, REG_GENERAL_EQ_OVERRIDE,
			   MASK_SET);
}

#ifdef CONFIG_USB_PD_TCPM_ITE_ON_CHIP
const struct cc_para_t *board_get_cc_tuning_parameter(enum usbpd_port port)
{
	const static struct cc_para_t
		cc_parameter[CONFIG_USB_PD_ITE_ACTIVE_PORT_COUNT] = { LISTIFY(
			CONFIG_USB_PD_ITE_ACTIVE_PORT_COUNT, ITE_CC_PARAMETER,
			(, )) };

	return &cc_parameter[port];
}
#endif

void board_reset_pd_mcu(void)
{
	/*
	 * C0 & C1: TCPC is embedded in the EC and processes interrupts in the
	 * chip code (it83xx/intc.c)
	 */
}

int board_set_active_charge_port(int port)
{
	int i;
	int is_valid_port =
		(port >= 0 && port < board_get_adjusted_usb_pd_port_count());
	/* adjust the actual port count when not the type-c db connected. */

	if (!is_valid_port && port != CHARGE_PORT_NONE) {
		return EC_ERROR_INVAL;
	}

	if (port == CHARGE_PORT_NONE) {
		/* Disable all ports. */
		for (i = 0; i < board_get_adjusted_usb_pd_port_count(); i++) {
			/*
			 * Do not return early if one fails otherwise we can
			 * get into a boot loop assertion failure.
			 */
			if (ppc_vbus_sink_enable(i, 0)) {
				CPRINTS("Disabling C%d as sink failed.", i);
			}
		}

		return EC_SUCCESS;
	}

	/* Check if the port is sourcing VBUS. */
	if (ppc_is_sourcing_vbus(port)) {
		CPRINTS("Skip enable C%d", port);
		return EC_ERROR_INVAL;
	}

	CPRINTS("New charge port: C%d", port);

	/*
	 * Turn off the other ports' sink path FETs, before enabling the
	 * requested charge port.
	 */
	for (i = 0; i < board_get_adjusted_usb_pd_port_count(); i++) {
		if (i == port) {
			continue;
		}

		if (ppc_vbus_sink_enable(i, 0)) {
			CPRINTS("C%d: sink path disable failed.", i);
		}
	}

	/* Enable requested charge port. */
	if (ppc_vbus_sink_enable(port, 1)) {
		CPRINTS("C%d: sink path enable failed.", port);
		return EC_ERROR_UNKNOWN;
	}

	return EC_SUCCESS;
}

#ifdef CONFIG_USB_PD_VBUS_MEASURE_ADC_EACH_PORT
enum adc_channel board_get_vbus_adc(int port)
{
	if (port == 0) {
		return ADC_VBUS_C0;
	}
	if (port == 1) {
		return ADC_VBUS_C1;
	}
	CPRINTSUSB("Unknown vbus adc port id: %d", port);
	return ADC_VBUS_C0;
}
#endif /* CONFIG_USB_PD_VBUS_MEASURE_ADC_EACH_PORT */
```

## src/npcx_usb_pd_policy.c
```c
/* Copyright 2022 The ChromiumOS Authors
 * Use of this source code is governed by a BSD-style license that can be
 * found in the LICENSE file.
 */

#include "baseboard_usbc_config.h"
#include "driver/tcpm/rt1718s.h"
#include "driver/tcpm/tcpm.h"
#include "usb_pd.h"
#include "usbc_ppc.h"

#define CPRINTS(format, args...) cprints(CC_USBCHARGE, format, ##args)
#define CPRINTF(format, args...) cprintf(CC_USBCHARGE, format, ##args)

int pd_snk_is_vbus_provided(int port)
{
	/* TODO: use ADC? */
	return tcpm_check_vbus_level(port, VBUS_PRESENT);
}
```

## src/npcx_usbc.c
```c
/* Copyright 2022 The ChromiumOS Authors
 * Use of this source code is governed by a BSD-style license that can be
 * found in the LICENSE file.
 */

/* Kingler board-specific USB-C configuration */

/* TODO(b/220196310): Create GPIO driver for RT17181S TCPC */
#ifdef __REQUIRE_ZEPHYR_GPIOS__
#undef __REQUIRE_ZEPHYR_GPIOS__
#endif

#include "baseboard_usbc_config.h"
#include "battery.h"
#include "console.h"
#include "driver/ppc/nx20p348x.h"
#include "driver/tcpm/anx7447.h"
#include "driver/tcpm/rt1718s.h"
#include "driver/usb_mux/ps8743_public.h"
#include "gpio.h"
#include "gpio/gpio_int.h"
#include "hooks.h"
#include "timer.h"
#include "usb_charge.h"
#include "usb_mux.h"
#include "usb_pd_tcpm.h"
#include "usbc_ppc.h"
#include "variant_db_detection.h"

#define CPRINTS(format, args...) cprints(CC_USBPD, format, ##args)
#define CPRINTF(format, args...) cprintf(CC_USBPD, format, ##args)

/* USB Mux */

/* USB Mux C1 : board_init of PS8743 */
int ps8743_mux_1_board_init(const struct usb_mux *me)
{
	ps8743_tune_usb_eq(me, PS8743_USB_EQ_TX_3_6_DB,
			   PS8743_USB_EQ_RX_16_0_DB);

	return EC_SUCCESS;
}

void board_usb_mux_init(void)
{
	if (corsola_get_db_type() == CORSOLA_DB_TYPEC) {
		/* Disable DCI function. This is not needed for ARM. */
		ps8743_field_update(usb_muxes[1].mux, PS8743_REG_DCI_CONFIG_2,
				    PS8743_AUTO_DCI_MODE_MASK,
				    PS8743_AUTO_DCI_MODE_FORCE_USB);
	}
}
DECLARE_HOOK(HOOK_INIT, board_usb_mux_init, HOOK_PRIO_INIT_I2C + 1);

void board_tcpc_init(void)
{
	/* Reset TCPC if we only we have a battery connected, or the SINK
	 * gpio to the PPC might be reset and cause brown-out.
	 */
	if (!system_jumped_late() && battery_is_present() == BP_YES) {
		/* TODO(crosbug.com/p/61098): How long do we need to wait? */
		board_reset_pd_mcu();
	}

#if CONFIG_USB_PD_PORT_MAX_COUNT > 1
	/* Do not enable TCPC interrupt on port 1 if not type-c */
	if (corsola_get_db_type() != CORSOLA_DB_TYPEC) {
		tcpc_config[USBC_PORT_C1].irq_gpio.port = NULL;
	}
#endif /* CONFIG_USB_PD_PORT_MAX_COUNT > 1 */

#ifdef CONFIG_PLATFORM_EC_USB_CHARGER
	/* Enable BC1.2 interrupts. */
	gpio_enable_dt_interrupt(GPIO_INT_FROM_NODELABEL(int_usb_c0_bc12));
#endif

	/*
	 * Initialize HPD to low; after sysjump SOC needs to see
	 * HPD pulse to enable video path
	 */
	for (int port = 0; port < CONFIG_USB_PD_PORT_MAX_COUNT; ++port) {
		usb_mux_hpd_update(port, USB_PD_MUX_HPD_LVL_DEASSERTED |
						 USB_PD_MUX_HPD_IRQ_DEASSERTED);
	}
}
DECLARE_HOOK(HOOK_INIT, board_tcpc_init, HOOK_PRIO_POST_I2C);

__override int board_rt1718s_init(int port)
{
	static bool gpio_initialized;

	/* Reset TCPC sink/source control when it's a power-on reset or has a
	 * battery. Do not alter the carried GPIO status or this might stop PPC
	 * sinking and brown-out the system when battery disconnected.
	 */
	if (!system_jumped_late() && !gpio_initialized &&
	    (battery_is_present() == BP_YES ||
	     (system_get_reset_flags() & EC_RESET_FLAG_POWER_ON))) {
		/* set GPIO 1~3 as push pull, as output, output low. */
		rt1718s_gpio_set_flags(port, RT1718S_GPIO1, GPIO_OUT_LOW);
		rt1718s_gpio_set_flags(port, RT1718S_GPIO2, GPIO_OUT_LOW);
		rt1718s_gpio_set_flags(port, RT1718S_GPIO3, GPIO_OUT_LOW);
		gpio_initialized = true;
	}

	/* gpio1 low, gpio2 output high when receiving frs signal */
	RETURN_ERROR(rt1718s_update_bits8(port, RT1718S_GPIO1_VBUS_CTRL,
					  RT1718S_GPIO_VBUS_CTRL_FRS_RX_VBUS,
					  0));
	/* GPIO1 EN_SNK high when received TCPCI SNK enabled command */
	RETURN_ERROR(rt1718s_update_bits8(
		port, RT1718S_GPIO1_VBUS_CTRL,
		RT1718S_GPIO_VBUS_CTRL_ENA_SNK_VBUS_GPIO, 0xFF));
	/* GPIO2 EN_SRC high when received TCPCI SRC enabled command */
	RETURN_ERROR(rt1718s_update_bits8(
		port, RT1718S_GPIO2_VBUS_CTRL,
		RT1718S_GPIO_VBUS_CTRL_FRS_RX_VBUS |
			RT1718S_GPIO_VBUS_CTRL_ENA_SRC_VBUS_GPIO,
		0xFF));

	/* Trigger GPIO 1/2 change when FRS signal received */
	RETURN_ERROR(rt1718s_update_bits8(
		port, RT1718S_FRS_CTRL3,
		RT1718S_FRS_CTRL3_FRS_RX_WAIT_GPIO2 |
			RT1718S_FRS_CTRL3_FRS_RX_WAIT_GPIO1,
		RT1718S_FRS_CTRL3_FRS_RX_WAIT_GPIO2 |
			RT1718S_FRS_CTRL3_FRS_RX_WAIT_GPIO1));
	/* Set FRS signal detect time to 46.875us */
	RETURN_ERROR(rt1718s_update_bits8(port, RT1718S_FRS_CTRL1,
					  RT1718S_FRS_CTRL1_FRSWAPRX_MASK,
					  0xFF));

	/* Disable BC1.2 SRC mode */
	RETURN_ERROR(rt1718s_update_bits8(port, RT1718S_RT2_BC12_SRC_FUNC,
					  RT1718S_RT2_BC12_SRC_FUNC_BC12_SRC_EN,
					  0));

#ifndef CONFIG_BC12_DETECT_RT1718S
	/*
	 * TODO(b:339533884) After BC1.2 is removed, the
	 * DPDM switch needs to be enabled.
	 */
	RETURN_ERROR(
		rt1718s_update_bits8(port, RT1718S_RT2_SBU_CTRL_01,
				     RT1718S_RT2_SBU_CTRL_01_DPDM_VIEN |
					     RT1718S_RT2_SBU_CTRL_01_DM_SWEN |
					     RT1718S_RT2_SBU_CTRL_01_DP_SWEN,
				     0xFF));
#endif

	return EC_SUCCESS;
}

#if CONFIG_USB_PD_PORT_MAX_COUNT > 1
__override int board_rt1718s_set_frs_enable(int port, int enable)
{
	if (port == USBC_PORT_C1)
		/*
		 * Use set_flags (implemented by a single i2c write) instead
		 * of set_level (= i2c_update) to save one read operation in
		 * FRS path.
		 */
		rt1718s_gpio_set_flags(port, GPIO_EN_USB_C1_FRS,
				       enable ? GPIO_OUT_HIGH : GPIO_OUT_LOW);
	return EC_SUCCESS;
}
#endif /* CONFIG_USB_PD_PORT_MAX_COUNT > 1 */

void board_reset_pd_mcu(void)
{
	CPRINTS("Resetting TCPCs...");
	/* reset C0 ANX3447 */
	/* Assert reset */
	gpio_pin_set_dt(&tcpc_config[0].rst_gpio, 1);
	k_msleep(1);
	gpio_pin_set_dt(&tcpc_config[0].rst_gpio, 0);
	/* After TEST_R release, anx7447/3447 needs 2ms to finish eFuse
	 * loading.
	 */
	k_msleep(2);

#if CONFIG_USB_PD_PORT_MAX_COUNT > 1
	/* reset C1 RT1718s */
	rt1718s_sw_reset(USBC_PORT_C1);

	/* set GPIO 1~3 as push pull, as output, output low. */
	rt1718s_gpio_set_flags(USBC_PORT_C1, RT1718S_GPIO1, GPIO_OUT_LOW);
	rt1718s_gpio_set_flags(USBC_PORT_C1, RT1718S_GPIO2, GPIO_OUT_LOW);
	rt1718s_gpio_set_flags(USBC_PORT_C1, RT1718S_GPIO3, GPIO_OUT_LOW);
#endif /* CONFIG_USB_PD_PORT_MAX_COUNT > 1 */
}

/* Used by Vbus discharge common code with CONFIG_USB_PD_DISCHARGE */
int board_vbus_source_enabled(int port)
{
	return ppc_is_sourcing_vbus(port);
}

#if CONFIG_USB_PD_PORT_MAX_COUNT > 1
__override int board_rt1718s_set_snk_enable(int port, int enable)
{
	rt1718s_gpio_set_level(port, GPIO_EN_USB_C1_SINK, enable);

	return EC_SUCCESS;
}
__override int board_rt1718s_set_src_enable(int port, int enable)
{
	rt1718s_gpio_set_level(port, GPIO_EN_USB_C1_SOURCE, enable);

	return EC_SUCCESS;
}
#endif /* CONFIG_USB_PD_PORT_MAX_COUNT > 1 */

int board_set_active_charge_port(int port)
{
	int i;
	bool is_valid_port =
		(port >= 0 && port < board_get_adjusted_usb_pd_port_count());
	/* adjust the actual port count when not the type-c db connected. */

	if (!is_valid_port && port != CHARGE_PORT_NONE) {
		return EC_ERROR_INVAL;
	}

	if (port == CHARGE_PORT_NONE) {
		CPRINTS("Disabling all charger ports");

		/* Disable all ports. */
		for (i = 0; i < board_get_adjusted_usb_pd_port_count(); i++) {
			/*
			 * Do not return early if one fails otherwise we can
			 * get into a boot loop assertion failure.
			 */
			if (ppc_vbus_sink_enable(i, 0)) {
				CPRINTS("Disabling C%d as sink failed.", i);
			}
		}

		return EC_SUCCESS;
	}

	/* Check if the port is sourcing VBUS. */
	if (ppc_is_sourcing_vbus(port)) {
		CPRINTS("Skip enable C%d", port);
		return EC_ERROR_INVAL;
	}

	CPRINTS("New charge port: C%d", port);

	/*
	 * Turn off the other ports' sink path FETs, before enabling the
	 * requested charge port.
	 */
	for (i = 0; i < board_get_adjusted_usb_pd_port_count(); i++) {
		if (i == port) {
			continue;
		}

		if (ppc_vbus_sink_enable(i, 0)) {
			CPRINTS("C%d: sink path disable failed.", i);
		}
	}

	/* Enable requested charge port. */
	if (ppc_vbus_sink_enable(port, 1)) {
		CPRINTS("C%d: sink path enable failed.", port);
		return EC_ERROR_UNKNOWN;
	}

	return EC_SUCCESS;
}

void ppc_interrupt(enum gpio_signal signal)
{
	switch (signal) {
	case GPIO_SIGNAL(DT_NODELABEL(gpio_usb_c0_ppc_int_odl)):
		ppc_chips[0].drv->interrupt(0);
		break;
	case GPIO_SIGNAL(DT_ALIAS(gpio_usb_c1_ppc_int_odl)):
		ppc_chips[1].drv->interrupt(1);
		break;
	default:
		break;
	}
}

#ifdef CONFIG_PLATFORM_EC_USB_CHARGER
void bc12_interrupt(enum gpio_signal signal)
{
	usb_charger_task_set_event(0, USB_CHG_EVENT_BC12);
}
#endif

__override int board_get_vbus_voltage(int port)
{
	int voltage = 0;
	int rv;

	switch (port) {
	case USBC_PORT_C0:
		rv = tcpc_config[USBC_PORT_C0].drv->get_vbus_voltage(port,
								     &voltage);
		if (rv)
			return 0;
		break;
#if CONFIG_USB_PD_PORT_MAX_COUNT > 1
	case USBC_PORT_C1:
		rt1718s_get_adc(port, RT1718S_ADC_VBUS1, &voltage);
		break;
#endif /* CONFIG_USB_PD_PORT_MAX_COUNT > 1 */
	default:
		return 0;
	}
	return voltage;
}

__override int board_nx20p348x_init(int port)
{
	int rv;

	rv = i2c_update8(ppc_chips[port].i2c_port,
			 ppc_chips[port].i2c_addr_flags,
			 NX20P348X_DEVICE_CONTROL_REG, NX20P348X_CTRL_LDO_SD,
			 MASK_SET);
	return rv;
}
```
